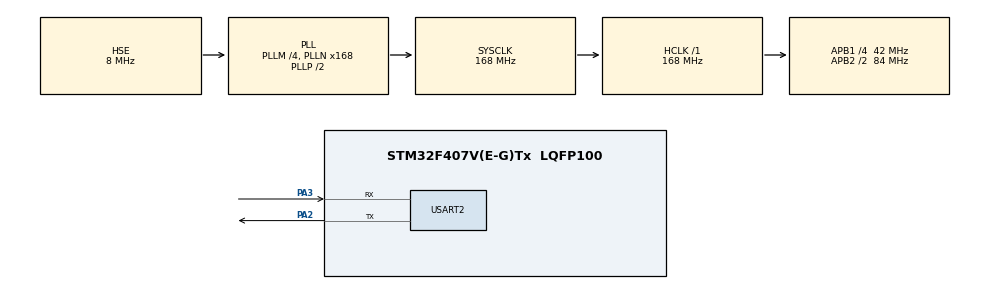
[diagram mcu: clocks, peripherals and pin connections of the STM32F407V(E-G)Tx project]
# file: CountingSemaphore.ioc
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FREERTOS.Tasks01=defaultTask,0,128,StartDefaultTask,Default,NULL,Dynamic,NULL,NULL
FREERTOS.configUSE_COUNTING_SEMAPHORES=1
Mcu.Family=STM32F4
Mcu.Name=STM32F407V(E-G)Tx
Mcu.Package=LQFP100
NVIC.PriorityGroup=NVIC_PRIORITYGROUP_4
NVIC.TIM6_DAC_IRQn=true\:15\:0\:false\:false\:true\:false\:false\:true
NVIC.TimeBase=TIM6_DAC_IRQn
NVIC.TimeBaseIP=TIM6
NVIC.USART2_IRQn=true\:5\:0\:false\:false\:true\:true\:true\:true
PA2.Mode=Asynchronous
PA2.Signal=USART2_TX
PA3.Mode=Asynchronous
PA3.Signal=USART2_RX
PH0-OSC_IN.Mode=HSE-External-Oscillator
PH0-OSC_IN.Signal=RCC_OSC_IN
PH1-OSC_OUT.Mode=HSE-External-Oscillator
PH1-OSC_OUT.Signal=RCC_OSC_OUT
ProjectManager.HeapSize=0x200
ProjectManager.StackSize=0x400
ProjectManager.TargetToolchain=STM32CubeIDE
RCC.48MHZClocksFreq_Value=84000000
RCC.AHBFreq_Value=168000000
RCC.APB1CLKDivider=RCC_HCLK_DIV4
RCC.APB1Freq_Value=42000000
RCC.APB1TimFreq_Value=84000000
RCC.APB2CLKDivider=RCC_HCLK_DIV2
RCC.APB2Freq_Value=84000000
RCC.APB2TimFreq_Value=168000000
RCC.CortexFreq_Value=168000000
RCC.HCLKFreq_Value=168000000
RCC.HSE_VALUE=8000000
RCC.HSI_VALUE=16000000
RCC.LSE_VALUE=32768
RCC.PLLM=4
RCC.PLLN=168
RCC.PLLSourceVirtual=RCC_PLLSOURCE_HSE
RCC.SYSCLKFreq_VALUE=168000000
RCC.SYSCLKSource=RCC_SYSCLKSOURCE_PLLCLK
RCC.VCOOutputFreq_Value=336000000
USART2.VirtualMode=VM_ASYNC
VP_FREERTOS_VS_CMSIS_V1.Mode=CMSIS_V1
VP_SYS_VS_tim6.Mode=TIM6
board=custom

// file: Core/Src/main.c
/* USER CODE BEGIN Header */
/**
  ******************************************************************************
  * @file           : main.c
  * @brief          : Main program body
  ******************************************************************************
  * @attention
  *
  * <h2><center>&copy; Copyright (c) 2021 STMicroelectronics.
  * All rights reserved.</center></h2>
  *
  * This software component is licensed by ST under BSD 3-Clause license,
  * the "License"; You may not use this file except in compliance with the
  * License. You may obtain a copy of the License at:
  *                        opensource.org/licenses/BSD-3-Clause
  *
  ******************************************************************************
  */
/* USER CODE END Header */
#include "main.h"
//#include "cmsis_os.h"

/* USER CODE BEGIN Includes */
#include "FreeRTOS.h"
#include "task.h"
#include "timers.h"
#include "queue.h"
#include "semphr.h"
#include "event_groups.h"

#include "stdlib.h"
#include "string.h"
/* USER CODE END Includes */

UART_HandleTypeDef huart2;

//osThreadId defaultTaskHandle;

void SystemClock_Config(void);
static void MX_GPIO_Init(void);
static void MX_USART2_UART_Init(void);
//void StartDefaultTask(void const * argument);

/* USER CODE BEGIN 0 */

// create task defines

TaskHandle_t HPThandler;
void HPT_TASK(void *pvParameters);

TaskHandle_t MPThandler;
void MPT_TASK(void *pvParameters);

TaskHandle_t LPThandler;
void LPT_TASK(void *pvParameters);

TaskHandle_t VLPThandler;
void VLPT_TASK(void *pvParameters);

// semaphore related
SemaphoreHandle_t CountingSem;

// resource related
int resource[3]={111,222,333};
int indx = 0;

//uart related
uint8_t rx_data = 0;

/* USER CODE END 0 */

int main(void)
{

  /* MCU Configuration--------------------------------------------------------*/

  /* Reset of all peripherals, Initializes the Flash interface and the Systick. */
  HAL_Init();

  /* Configure the system clock */
  SystemClock_Config();

  /* Initialize all configured peripherals */
  MX_GPIO_Init();
  MX_USART2_UART_Init();
  /* USER CODE BEGIN 2 */

  HAL_UART_Receive_IT(&huart2, &rx_data, 1);

  CountingSem = xSemaphoreCreateCounting(3,0);
  if (CountingSem == NULL) HAL_UART_Transmit(&huart2,(uint8_t *)"Unable to Create Semaphore\n\n",28,100);
  else HAL_UART_Transmit(&huart2,(uint8_t *)"Couting Semaphore created successfully\n\n",41,1000);

  //create TASKS

  xTaskCreate(HPT_TASK, "HPT", 128, NULL, 3, &HPThandler);
  xTaskCreate(MPT_TASK, "MPT", 128, NULL, 2, &MPThandler);
  xTaskCreate(LPT_TASK, "LPT", 128, NULL, 1, &LPThandler);
  xTaskCreate(VLPT_TASK, "VLPT", 128, NULL, 0, &VLPThandler);

  vTaskStartScheduler();

  /* USER CODE END 2 */

  /* Create the thread(s) */
  /* definition and creation of defaultTask */
  //osThreadDef(defaultTask, StartDefaultTask, osPriorityNormal, 0, 128);
  //defaultTaskHandle = osThreadCreate(osThread(defaultTask), NULL);

  /* Start scheduler */
  //osKernelStart();

  /* We should never get here as control is now taken by the scheduler */
  /* Infinite loop */
  while (1)
  {

  }
}

void SystemClock_Config(void)
{
  RCC_OscInitTypeDef RCC_OscInitStruct = {0};
  RCC_ClkInitTypeDef RCC_ClkInitStruct = {0};

  /** Configure the main internal regulator output voltage
  */
  __HAL_RCC_PWR_CLK_ENABLE();
  __HAL_PWR_VOLTAGESCALING_CONFIG(PWR_REGULATOR_VOLTAGE_SCALE1);
  /** Initializes the RCC Oscillators according to the specified parameters
  * in the RCC_OscInitTypeDef structure.
  */
  RCC_OscInitStruct.OscillatorType = RCC_OSCILLATORTYPE_HSE;
  RCC_OscInitStruct.HSEState = RCC_HSE_ON;
  RCC_OscInitStruct.PLL.PLLState = RCC_PLL_ON;
  RCC_OscInitStruct.PLL.PLLSource = RCC_PLLSOURCE_HSE;
  RCC_OscInitStruct.PLL.PLLM = 4;
  RCC_OscInitStruct.PLL.PLLN = 168;
  RCC_OscInitStruct.PLL.PLLP = RCC_PLLP_DIV2;
  RCC_OscInitStruct.PLL.PLLQ = 4;
  if (HAL_RCC_OscConfig(&RCC_OscInitStruct) != HAL_OK)
  {
    Error_Handler();
  }
  /** Initializes the CPU, AHB and APB buses clocks
  */
  RCC_ClkInitStruct.ClockType = RCC_CLOCKTYPE_HCLK|RCC_CLOCKTYPE_SYSCLK
                              |RCC_CLOCKTYPE_PCLK1|RCC_CLOCKTYPE_PCLK2;
  RCC_ClkInitStruct.SYSCLKSource = RCC_SYSCLKSOURCE_PLLCLK;
  RCC_ClkInitStruct.AHBCLKDivider = RCC_SYSCLK_DIV1;
  RCC_ClkInitStruct.APB1CLKDivider = RCC_HCLK_DIV4;
  RCC_ClkInitStruct.APB2CLKDivider = RCC_HCLK_DIV2;

  if (HAL_RCC_ClockConfig(&RCC_ClkInitStruct, FLASH_LATENCY_5) != HAL_OK)
  {
    Error_Handler();
  }
}

static void MX_USART2_UART_Init(void)
{

  huart2.Instance = USART2;
  huart2.Init.BaudRate = 115200;
  huart2.Init.WordLength = UART_WORDLENGTH_8B;
  huart2.Init.StopBits = UART_STOPBITS_1;
  huart2.Init.Parity = UART_PARITY_NONE;
  huart2.Init.Mode = UART_MODE_TX_RX;
  huart2.Init.HwFlowCtl = UART_HWCONTROL_NONE;
  huart2.Init.OverSampling = UART_OVERSAMPLING_16;
  if (HAL_UART_Init(&huart2) != HAL_OK)
  {
    Error_Handler();
  }

}

static void MX_GPIO_Init(void)
{

  /* GPIO Ports Clock Enable */
  __HAL_RCC_GPIOH_CLK_ENABLE();
  __HAL_RCC_GPIOA_CLK_ENABLE();

}

/* USER CODE BEGIN 4 */

void HAL_UART_RxCpltCallback(UART_HandleTypeDef *huart)
{
	HAL_UART_Receive_IT(&huart2,&rx_data, 1);
	if(rx_data=='r')
	{
		//release semaphore
		//the xHigherPriorityTaskWoken parameter must be initialized to pdFALSE as
		//it will get set to pdTRUE inside the interrupt safe API function if a
		// context switch is required
		BaseType_t xHigherPriorityTaskToken = pdFALSE;
		xSemaphoreGiveFromISR(CountingSem,&xHigherPriorityTaskToken);//ISR SAFE VERSION
		xSemaphoreGiveFromISR(CountingSem,&xHigherPriorityTaskToken);//ISR SAFE VERSION
		xSemaphoreGiveFromISR(CountingSem,&xHigherPriorityTaskToken);//ISR SAFE VERSION

		/* Pass the xHigherPriorityTaskWoken value into portEND_SWITCHING_ISR(). If
		 xHigherPriorityTaskWoken was set to pdTRUE inside xSemaphoreGiveFromISR()
		 then calling portEND_SWITCHING_ISR() will request a context switch. If
		 xHigherPriorityTaskWoken is still pdFALSE then calling
		 portEND_SWITCHING_ISR() will have no effect */

		portEND_SWITCHING_ISR(xHigherPriorityTaskToken);
	}

}

void HPT_TASK(void *pvParameters)
{
	char sresource[3];
	int semcount = 0;
	char ssemcount[2];

	//Give 3 semaphores at the beginning...
	xSemaphoreGive(CountingSem);
	xSemaphoreGive(CountingSem);
	xSemaphoreGive(CountingSem);

	while(1)
	{
		char str[150];
		strcpy(str,"Entered HPT Task\n About to ACQUIRE the Semaphore\n\n");
		semcount = uxSemaphoreGetCount(CountingSem);
		itoa (semcount, ssemcount, 10);
		strcat (str, "Tokens available are: ");
		strcat (str, ssemcount);
		strcat (str, "\n\n");
		HAL_UART_Transmit(&huart2,(uint8_t *)str,strlen(str),HAL_MAX_DELAY);

		xSemaphoreTake(CountingSem,portMAX_DELAY);

		itoa(resource[indx],sresource,10);
		strcpy(str,"Leaving HPT Task\n Data ACCEDDED is:: ");
		strcat(str,sresource);
		strcat(str,"\n Not releasing the Semaphore \n\n\n");
		HAL_UART_Transmit(&huart2,(uint8_t *)str,strlen(str),HAL_MAX_DELAY);

		indx++;
		if(indx>2) indx=0;
		vTaskDelay(3000);
		//vTaskDelete(NULL);
	}

}

void MPT_TASK(void *pvParameters)
{
	char sresource[3];
	int semcount = 0;
	char ssemcount[2];

	//Give 3 semaphores at the beginning...
//	xSemaphoreGive(CountingSem);
//	xSemaphoreGive(CountingSem);
//	xSemaphoreGive(CountingSem);

	while(1)
	{
		char str[150];
		strcpy(str,"Entered MPT Task\n About to ACQUIRE the Semaphore\n\n");
		semcount = uxSemaphoreGetCount(CountingSem);
		itoa (semcount, ssemcount, 10);
		strcat (str, "Tokens available are: ");
		strcat (str, ssemcount);
		strcat (str, "\n\n");
		HAL_UART_Transmit(&huart2,(uint8_t *)str,strlen(str),HAL_MAX_DELAY);

		xSemaphoreTake(CountingSem,portMAX_DELAY);

		itoa(resource[indx],sresource,10);
		strcpy(str,"Leaving MPT Task\n Data ACCEDDED is:: ");
		strcat(str,sresource);
		strcat(str,"\n Not releasing the Semaphore \n\n\n");
		HAL_UART_Transmit(&huart2,(uint8_t *)str,strlen(str),HAL_MAX_DELAY);

		indx++;
		if(indx>2) indx=0;
		vTaskDelay(2000);
//		vTaskDelete(NULL);
	}

}
void LPT_TASK(void *pvParameters)
{
	char sresource[3];
	int semcount = 0;
	char ssemcount[2];

	//Give 3 semaphores at the beginning...
//	xSemaphoreGive(CountingSem);
//	xSemaphoreGive(CountingSem);
//	xSemaphoreGive(CountingSem);

	while(1)
	{
		char str[150];
		strcpy(str,"Entered LPT Task\n About to ACQUIRE the Semaphore\n\n");
		semcount = uxSemaphoreGetCount(CountingSem);
		itoa (semcount, ssemcount, 10);
		strcat (str, "Tokens available are: ");
		strcat (str, ssemcount);
		strcat (str, "\n\n");
		HAL_UART_Transmit(&huart2,(uint8_t *)str,strlen(str),HAL_MAX_DELAY);

		xSemaphoreTake(CountingSem,portMAX_DELAY);

		itoa(resource[indx],sresource,10);
		strcpy(str,"Leaving LPT Task\n Data ACCEDDED is:: ");
		strcat(str,sresource);
		strcat(str,"\n Not releasing the Semaphore \n\n\n");
		HAL_UART_Transmit(&huart2,(uint8_t *)str,strlen(str),HAL_MAX_DELAY);

		indx++;
		if(indx>2) indx=0;
		vTaskDelay(1000);
//		vTaskDelete(NULL);
	}
}

void VLPT_TASK(void *pvParameters)
{
	char sresource[3];
	int semcount = 0;
	char ssemcount[2];

	//Give 3 semaphores at the beginning...
//	xSemaphoreGive(CountingSem);
//	xSemaphoreGive(CountingSem);
//	xSemaphoreGive(CountingSem);

	while(1)
	{
		char str[150];
		strcpy(str,"Entered VLPT Task\n About to ACQUIRE the Semaphore\n\n");
		semcount = uxSemaphoreGetCount(CountingSem);
		itoa (semcount, ssemcount, 10);
		strcat (str, "Tokens available are: ");
		strcat (str, ssemcount);
		strcat (str, "\n\n");
		HAL_UART_Transmit(&huart2,(uint8_t *)str,strlen(str),HAL_MAX_DELAY);

		xSemaphoreTake(CountingSem,portMAX_DELAY);

		itoa(resource[indx],sresource,10);
		strcpy(str,"Leaving VLPT Task\n Data ACCEDDED is:: ");
		strcat(str,sresource);
		strcat(str,"\n Not releasing the Semaphore \n\n\n");
		HAL_UART_Transmit(&huart2,(uint8_t *)str,strlen(str),HAL_MAX_DELAY);

		indx++;
		if(indx>2) indx=0;
		vTaskDelay(500);
	}

}

/* USER CODE END 4 */

//void StartDefaultTask(void const * argument)
//{
//  /* USER CODE BEGIN 5 */
//  /* Infinite loop */
//  for(;;)
//  {
//    osDelay(1);
//  }
//  /* USER CODE END 5 */
//}

void HAL_TIM_PeriodElapsedCallback(TIM_HandleTypeDef *htim)
{
  if (htim->Instance == TIM6) {
    HAL_IncTick();
  }
}

void Error_Handler(void)
{
  __disable_irq();
  while (1)
  {
  }
}

/************************ (C) COPYRIGHT STMicroelectronics *****END OF FILE****/
